AUTOSAR XML (schema 00046)
package /ComponentTypes
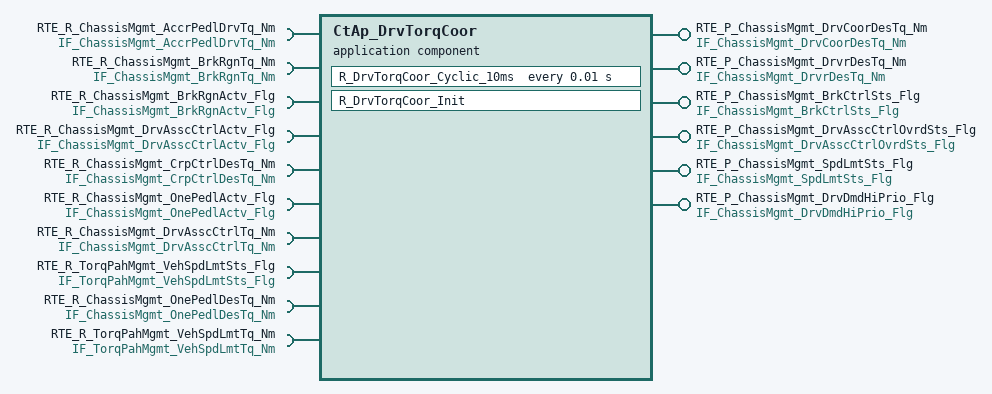
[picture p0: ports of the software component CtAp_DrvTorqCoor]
  application sw component type CtAp_DrvTorqCoor
    6 x provide port:
      RTE_P_ChassisMgmt_DrvCoorDesTq_Nm: nonqueued-sender-com-spec{data-element=tec_ChassisMgmt_DrvCoorDesTq_Nm, init-value=0}, provided-interface=IF_ChassisMgmt_DrvCoorDesTq_Nm
      RTE_P_ChassisMgmt_DrvrDesTq_Nm: nonqueued-sender-com-spec{data-element=tec_ChassisMgmt_DrvrDesTq_Nm, init-value=0}, provided-interface=IF_ChassisMgmt_DrvrDesTq_Nm
      RTE_P_ChassisMgmt_BrkCtrlSts_Flg: nonqueued-sender-com-spec{data-element=tec_ChassisMgmt_BrkCtrlSts_Flg, init-value=0}, provided-interface=IF_ChassisMgmt_BrkCtrlSts_Flg
      RTE_P_ChassisMgmt_DrvAsscCtrlOvrdSts_Flg: nonqueued-sender-com-spec{data-element=tec_ChassisMgmt_DrvAsscCtrlOvrdSts_Flg, init-value=0}, provided-interface=IF_ChassisMgmt_DrvAsscCtrlOvrdSts_Flg
      RTE_P_ChassisMgmt_SpdLmtSts_Flg: nonqueued-sender-com-spec{data-element=tec_ChassisMgmt_SpdLmtSts_Flg, init-value=0}, provided-interface=IF_ChassisMgmt_SpdLmtSts_Flg
      RTE_P_ChassisMgmt_DrvDmdHiPrio_Flg: nonqueued-sender-com-spec{data-element=tec_ChassisMgmt_DrvDmdHiPrio_Flg, init-value=0}, provided-interface=IF_ChassisMgmt_DrvDmdHiPrio_Flg
    10 x require port:
      RTE_R_ChassisMgmt_AccrPedlDrvTq_Nm: nonqueued-receiver-com-spec{data-element=tec_ChassisMgmt_AccrPedlDrvTq_Nm, filter=data-filter-type=ALWAYS, init-value=0}, required-interface=IF_ChassisMgmt_AccrPedlDrvTq_Nm
      RTE_R_ChassisMgmt_BrkRgnTq_Nm: nonqueued-receiver-com-spec{data-element=tec_ChassisMgmt_BrkRgnTq_Nm, filter=data-filter-type=ALWAYS, init-value=0}, required-interface=IF_ChassisMgmt_BrkRgnTq_Nm
      RTE_R_ChassisMgmt_BrkRgnActv_Flg: nonqueued-receiver-com-spec{data-element=tec_ChassisMgmt_BrkRgnActv_Flg, filter=data-filter-type=ALWAYS, init-value=0}, required-interface=IF_ChassisMgmt_BrkRgnActv_Flg
      RTE_R_ChassisMgmt_DrvAsscCtrlActv_Flg: nonqueued-receiver-com-spec{data-element=tec_ChassisMgmt_DrvAsscCtrlActv_Flg, filter=data-filter-type=ALWAYS, init-value=0}, required-interface=IF_ChassisMgmt_DrvAsscCtrlActv_Flg
      RTE_R_ChassisMgmt_CrpCtrlDesTq_Nm: nonqueued-receiver-com-spec{data-element=tec_ChassisMgmt_CrpCtrlDesTq_Nm, filter=data-filter-type=ALWAYS, init-value=0}, required-interface=IF_ChassisMgmt_CrpCtrlDesTq_Nm
      RTE_R_ChassisMgmt_OnePedlActv_Flg: nonqueued-receiver-com-spec{data-element=tec_ChassisMgmt_OnePedlActv_Flg, filter=data-filter-type=ALWAYS, init-value=0}, required-interface=IF_ChassisMgmt_OnePedlActv_Flg
      RTE_R_ChassisMgmt_DrvAsscCtrlTq_Nm: nonqueued-receiver-com-spec{data-element=tec_ChassisMgmt_DrvAsscCtrlTq_Nm, filter=data-filter-type=ALWAYS, init-value=0}, required-interface=IF_ChassisMgmt_DrvAsscCtrlTq_Nm
      RTE_R_TorqPahMgmt_VehSpdLmtSts_Flg: nonqueued-receiver-com-spec{data-element=tec_TorqPahMgmt_VehSpdLmtSts_Flg, filter=data-filter-type=ALWAYS, init-value=0}, required-interface=IF_TorqPahMgmt_VehSpdLmtSts_Flg
      RTE_R_ChassisMgmt_OnePedlDesTq_Nm: nonqueued-receiver-com-spec{data-element=tec_ChassisMgmt_OnePedlDesTq_Nm, filter=data-filter-type=ALWAYS, init-value=0}, required-interface=IF_ChassisMgmt_OnePedlDesTq_Nm
      RTE_R_TorqPahMgmt_VehSpdLmtTq_Nm: nonqueued-receiver-com-spec{data-element=tec_TorqPahMgmt_VehSpdLmtTq_Nm, filter=data-filter-type=ALWAYS, init-value=0}, required-interface=IF_TorqPahMgmt_VehSpdLmtTq_Nm
    behavior CtAp_DrvTorqCoor_InternalBehavior
      init event CtAp_DrvTorqCoor_InitEvent: start-on-event=R_DrvTorqCoor_Init
      timing event TMT_R_DrvTorqCoor_Cyclic_10ms: start-on-event=R_DrvTorqCoor_Cyclic_10ms, period=0.01
      runnable R_DrvTorqCoor_Init
      runnable R_DrvTorqCoor_Cyclic_10ms
        data-receive-point-by-arguments:
          10 x access:
            REC_RTE_R_ChassisMgmt_AccrPedlDrvTq_Nm_tec_ChassisMgmt_AccrPedlDrvTq_Nm: accessed-variable=RTE_R_ChassisMgmt_AccrPedlDrvTq_Nm.tec_ChassisMgmt_AccrPedlDrvTq_Nm
            REC_RTE_R_ChassisMgmt_BrkRgnActv_Flg_tec_ChassisMgmt_BrkRgnActv_Flg: accessed-variable=RTE_R_ChassisMgmt_BrkRgnActv_Flg.tec_ChassisMgmt_BrkRgnActv_Flg
            REC_RTE_R_ChassisMgmt_BrkRgnTq_Nm_tec_ChassisMgmt_BrkRgnTq_Nm: accessed-variable=RTE_R_ChassisMgmt_BrkRgnTq_Nm.tec_ChassisMgmt_BrkRgnTq_Nm
            REC_RTE_R_ChassisMgmt_CrpCtrlDesTq_Nm_tec_ChassisMgmt_CrpCtrlDesTq_Nm: accessed-variable=RTE_R_ChassisMgmt_CrpCtrlDesTq_Nm.tec_ChassisMgmt_CrpCtrlDesTq_Nm
            REC_RTE_R_ChassisMgmt_DrvAsscCtrlActv_Flg_tec_ChassisMgmt_DrvAsscCtrlActv_Flg: accessed-variable=RTE_R_ChassisMgmt_DrvAsscCtrlActv_Flg.tec_ChassisMgmt_DrvAsscCtrlActv_Flg
            REC_RTE_R_ChassisMgmt_DrvAsscCtrlTq_Nm_tec_ChassisMgmt_DrvAsscCtrlTq_Nm: accessed-variable=RTE_R_ChassisMgmt_DrvAsscCtrlTq_Nm.tec_ChassisMgmt_DrvAsscCtrlTq_Nm
            REC_RTE_R_ChassisMgmt_OnePedlActv_Flg_tec_ChassisMgmt_OnePedlActv_Flg: accessed-variable=RTE_R_ChassisMgmt_OnePedlActv_Flg.tec_ChassisMgmt_OnePedlActv_Flg
            REC_RTE_R_ChassisMgmt_OnePedlDesTq_Nm_tec_ChassisMgmt_OnePedlDesTq_Nm: accessed-variable=RTE_R_ChassisMgmt_OnePedlDesTq_Nm.tec_ChassisMgmt_OnePedlDesTq_Nm
            REC_RTE_R_TorqPahMgmt_VehSpdLmtSts_Flg_tec_TorqPahMgmt_VehSpdLmtSts_Flg: accessed-variable=RTE_R_TorqPahMgmt_VehSpdLmtSts_Flg.tec_TorqPahMgmt_VehSpdLmtSts_Flg
            REC_RTE_R_TorqPahMgmt_VehSpdLmtTq_Nm_tec_TorqPahMgmt_VehSpdLmtTq_Nm: accessed-variable=RTE_R_TorqPahMgmt_VehSpdLmtTq_Nm.tec_TorqPahMgmt_VehSpdLmtTq_Nm
        data-send-points:
          6 x access:
            SEND_RTE_P_ChassisMgmt_BrkCtrlSts_Flg_tec_ChassisMgmt_BrkCtrlSts_Flg: accessed-variable=RTE_P_ChassisMgmt_BrkCtrlSts_Flg.tec_ChassisMgmt_BrkCtrlSts_Flg
            SEND_RTE_P_ChassisMgmt_DrvAsscCtrlOvrdSts_Flg_tec_ChassisMgmt_DrvAsscCtrlOvrdSts_Flg: accessed-variable=RTE_P_ChassisMgmt_DrvAsscCtrlOvrdSts_Flg.tec_ChassisMgmt_DrvAsscCtrlOvrdSts_Flg
            SEND_RTE_P_ChassisMgmt_DrvCoorDesTq_Nm_tec_ChassisMgmt_DrvCoorDesTq_Nm: accessed-variable=RTE_P_ChassisMgmt_DrvCoorDesTq_Nm.tec_ChassisMgmt_DrvCoorDesTq_Nm
            SEND_RTE_P_ChassisMgmt_DrvDmdHiPrio_Flg_tec_ChassisMgmt_DrvDmdHiPrio_Flg: accessed-variable=RTE_P_ChassisMgmt_DrvDmdHiPrio_Flg.tec_ChassisMgmt_DrvDmdHiPrio_Flg
            SEND_RTE_P_ChassisMgmt_DrvrDesTq_Nm_tec_ChassisMgmt_DrvrDesTq_Nm: accessed-variable=RTE_P_ChassisMgmt_DrvrDesTq_Nm.tec_ChassisMgmt_DrvrDesTq_Nm
            SEND_RTE_P_ChassisMgmt_SpdLmtSts_Flg_tec_ChassisMgmt_SpdLmtSts_Flg: accessed-variable=RTE_P_ChassisMgmt_SpdLmtSts_Flg.tec_ChassisMgmt_SpdLmtSts_Flg
  swc implementation CtAp_DrvTorqCoor_Implementation: behavior=CtAp_DrvTorqCoor_InternalBehavior
    code-descriptors:
      code Default: artifact-descriptors=autosar-engineering-object=category=SWOBJ
